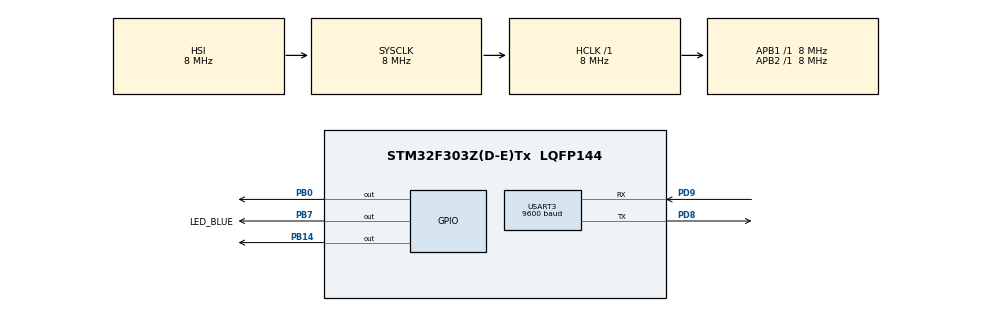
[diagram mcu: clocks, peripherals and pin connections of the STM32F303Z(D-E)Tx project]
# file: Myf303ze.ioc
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Mcu.Family=STM32F3
Mcu.Name=STM32F303Z(D-E)Tx
Mcu.Package=LQFP144
NVIC.PriorityGroup=NVIC_PRIORITYGROUP_4
NVIC.USART3_IRQn=true\:0\:0\:false\:false\:true\:true\:true
PB0.Signal=GPIO_Output
PB14.PinState=GPIO_PIN_SET
PB14.Signal=GPIO_Output
PB7.GPIO_Label=LED_BLUE
PB7.Signal=GPIO_Output
PD8.Mode=Asynchronous
PD8.Signal=USART3_TX
PD9.Mode=Asynchronous
PD9.Signal=USART3_RX
ProjectManager.HeapSize=0x200
ProjectManager.StackSize=0x400
ProjectManager.TargetToolchain=Makefile
RCC.AHBFreq_Value=8000000
RCC.APB1Freq_Value=8000000
RCC.APB1TimFreq_Value=8000000
RCC.APB2Freq_Value=8000000
RCC.APB2TimFreq_Value=8000000
RCC.CortexFreq_Value=8000000
RCC.HCLKFreq_Value=8000000
RCC.HSE_VALUE=8000000
RCC.HSI_VALUE=8000000
RCC.LSE_VALUE=32768
RCC.SYSCLKFreq_VALUE=8000000
RCC.USBFreq_Value=16000000
USART3.BaudRate=9600
USART3.VirtualMode-Asynchronous=VM_ASYNC
board=custom

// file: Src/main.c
/* USER CODE BEGIN Header */
/**
  ******************************************************************************
  * @file           : main.c
  * @brief          : Main program body
  ******************************************************************************
  * @attention
  *
  * <h2><center>&copy; Copyright (c) 2021 STMicroelectronics.
  * All rights reserved.</center></h2>
  *
  * This software component is licensed by ST under BSD 3-Clause license,
  * the "License"; You may not use this file except in compliance with the
  * License. You may obtain a copy of the License at:
  *                        opensource.org/licenses/BSD-3-Clause
  *
  ******************************************************************************
  */
/* USER CODE END Header */
#include "main.h"

UART_HandleTypeDef huart3;

void SystemClock_Config(void);
static void MX_GPIO_Init(void);
static void MX_USART3_UART_Init(void);

/* USER CODE BEGIN 0 */

static void thread_1(void){

  //toggle blue LED every 200ms
  while (1)
  {
    HAL_GPIO_TogglePin(GPIOB,GPIO_PIN_7);
    taskDelay(50);
  }

}

uint8_t shell_rxBuffer[4] = {0};

/* USER CODE END 0 */

int main(void)
{

  /* MCU Configuration--------------------------------------------------------*/

  /* Reset of all peripherals, Initializes the Flash interface and the Systick. */
  HAL_Init();

  /* Configure the system clock */
  SystemClock_Config();

  /* Initialize all configured peripherals */
  MX_GPIO_Init();
  MX_USART3_UART_Init();
  /* USER CODE BEGIN 2 */

  KernelInit();

  isoShell_init(&huart3);
  HAL_UART_Receive_IT(&huart3, shell_rxBuffer, 1);

  TaskCreate("blue led",DEFAULT_TASK_SIZE,thread_1,100);

  KernelStart();

  /* USER CODE END 2 */

  /* Infinite loop */
  while (1)
  {

  }
}

void SystemClock_Config(void)
{
  RCC_OscInitTypeDef RCC_OscInitStruct = {0};
  RCC_ClkInitTypeDef RCC_ClkInitStruct = {0};
  RCC_PeriphCLKInitTypeDef PeriphClkInit = {0};

  /** Initializes the RCC Oscillators according to the specified parameters
  * in the RCC_OscInitTypeDef structure.
  */
  RCC_OscInitStruct.OscillatorType = RCC_OSCILLATORTYPE_HSI;
  RCC_OscInitStruct.HSIState = RCC_HSI_ON;
  RCC_OscInitStruct.HSICalibrationValue = RCC_HSICALIBRATION_DEFAULT;
  RCC_OscInitStruct.PLL.PLLState = RCC_PLL_NONE;
  if (HAL_RCC_OscConfig(&RCC_OscInitStruct) != HAL_OK)
  {
    Error_Handler();
  }
  /** Initializes the CPU, AHB and APB buses clocks
  */
  RCC_ClkInitStruct.ClockType = RCC_CLOCKTYPE_HCLK|RCC_CLOCKTYPE_SYSCLK
                              |RCC_CLOCKTYPE_PCLK1|RCC_CLOCKTYPE_PCLK2;
  RCC_ClkInitStruct.SYSCLKSource = RCC_SYSCLKSOURCE_HSI;
  RCC_ClkInitStruct.AHBCLKDivider = RCC_SYSCLK_DIV1;
  RCC_ClkInitStruct.APB1CLKDivider = RCC_HCLK_DIV1;
  RCC_ClkInitStruct.APB2CLKDivider = RCC_HCLK_DIV1;

  if (HAL_RCC_ClockConfig(&RCC_ClkInitStruct, FLASH_LATENCY_0) != HAL_OK)
  {
    Error_Handler();
  }
  PeriphClkInit.PeriphClockSelection = RCC_PERIPHCLK_USART3;
  PeriphClkInit.Usart3ClockSelection = RCC_USART3CLKSOURCE_PCLK1;
  if (HAL_RCCEx_PeriphCLKConfig(&PeriphClkInit) != HAL_OK)
  {
    Error_Handler();
  }
}

static void MX_USART3_UART_Init(void)
{

  huart3.Instance = USART3;
  huart3.Init.BaudRate = 9600;
  huart3.Init.WordLength = UART_WORDLENGTH_8B;
  huart3.Init.StopBits = UART_STOPBITS_1;
  huart3.Init.Parity = UART_PARITY_NONE;
  huart3.Init.Mode = UART_MODE_TX_RX;
  huart3.Init.HwFlowCtl = UART_HWCONTROL_NONE;
  huart3.Init.OverSampling = UART_OVERSAMPLING_16;
  huart3.Init.OneBitSampling = UART_ONE_BIT_SAMPLE_DISABLE;
  huart3.AdvancedInit.AdvFeatureInit = UART_ADVFEATURE_NO_INIT;
  if (HAL_UART_Init(&huart3) != HAL_OK)
  {
    Error_Handler();
  }

}

static void MX_GPIO_Init(void)
{
  GPIO_InitTypeDef GPIO_InitStruct = {0};

  /* GPIO Ports Clock Enable */
  __HAL_RCC_GPIOB_CLK_ENABLE();
  __HAL_RCC_GPIOD_CLK_ENABLE();

  /*Configure GPIO pin Output Level */
  HAL_GPIO_WritePin(GPIOB, GPIO_PIN_0|LED_BLUE_Pin, GPIO_PIN_RESET);

  /*Configure GPIO pin Output Level */
  HAL_GPIO_WritePin(GPIOB, GPIO_PIN_14, GPIO_PIN_SET);

  /*Configure GPIO pins : PB0 PB14 LED_BLUE_Pin */
  GPIO_InitStruct.Pin = GPIO_PIN_0|GPIO_PIN_14|LED_BLUE_Pin;
  GPIO_InitStruct.Mode = GPIO_MODE_OUTPUT_PP;
  GPIO_InitStruct.Pull = GPIO_NOPULL;
  GPIO_InitStruct.Speed = GPIO_SPEED_FREQ_LOW;
  HAL_GPIO_Init(GPIOB, &GPIO_InitStruct);

}

/* USER CODE BEGIN 4 */

void HAL_UART_RxCpltCallback(UART_HandleTypeDef *huart)
{
  isoShell_main(shell_rxBuffer);
  HAL_UART_Receive_IT(&huart3, shell_rxBuffer, 1);
}

/* USER CODE END 4 */

void Error_Handler(void)
{
  __disable_irq();
  while (1)
  {
  }
}

/************************ (C) COPYRIGHT STMicroelectronics *****END OF FILE****/
